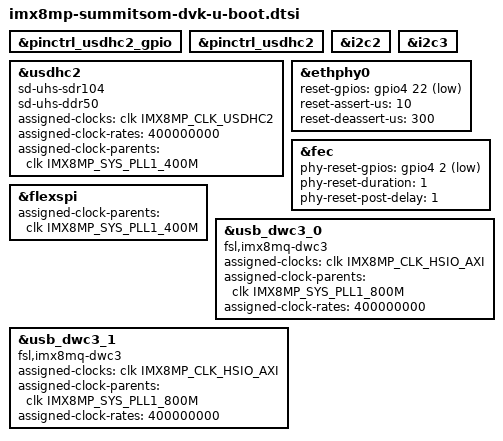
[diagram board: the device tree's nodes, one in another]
// SPDX-License-Identifier: GPL-2.0+
/*
 * Copyright 2021 Ezurio
 */

#include "imx8mp-summitsom-u-boot.dtsi"

&pinctrl_usdhc2_gpio {
	bootph-pre-ram;
};

&pinctrl_usdhc2 {
	bootph-pre-ram;
};

&i2c2 {
	bootph-pre-ram;
};

&i2c3 {
	bootph-pre-ram;
};

&usdhc2 {
	bootph-pre-ram;
	sd-uhs-sdr104;
	sd-uhs-ddr50;
	assigned-clocks = <&clk IMX8MP_CLK_USDHC2>;
	assigned-clock-rates = <400000000>;
	assigned-clock-parents = <&clk IMX8MP_SYS_PLL1_400M>;
};

&ethphy0 {
	reset-gpios = <&gpio4 22 GPIO_ACTIVE_LOW>;
	reset-assert-us = <10>;
	reset-deassert-us = <300>;
};

&fec {
	phy-reset-gpios = <&gpio4 2 GPIO_ACTIVE_LOW>;
	phy-reset-duration = <1>;
	phy-reset-post-delay = <1>;
};

&flexspi {
	assigned-clock-parents = <&clk IMX8MP_SYS_PLL1_400M>;
};

&usb_dwc3_0 {
	compatible = "fsl,imx8mq-dwc3", "snps,dwc3";
	assigned-clocks = <&clk IMX8MP_CLK_HSIO_AXI>;
	assigned-clock-parents = <&clk IMX8MP_SYS_PLL1_800M>;
	assigned-clock-rates = <400000000>;
};

&usb_dwc3_1 {
	compatible = "fsl,imx8mq-dwc3", "snps,dwc3";
	assigned-clocks = <&clk IMX8MP_CLK_HSIO_AXI>;
	assigned-clock-parents = <&clk IMX8MP_SYS_PLL1_800M>;
	assigned-clock-rates = <400000000>;
};
